VERSION "f33"
NS_ :

BS_:
BU_: RR RL FL FR GEN

CM_ "Dummy messages for use in the C files. These will never be sent over CAN,
    it is only to make the C code more generic";

BO_ 000 ERPM_DUTY_VOLTAGE: 8 GEN
 SG_ ERPM : 7|32@1- (1,0) [-120000|1200000] "" Vector__XXX
 SG_ Duty : 39|16@1- (0.1,0) [-100|100] "%" Vector__XXX
 SG_ InputVoltage : 55|16@1- (1,0) [0|1000] "V" Vector__XXX

BO_ 001 AC_DC_CURRENT: 8 GEN
 SG_ AC_Current : 7|16@0- (0.1,0) [-850|850] "A"  Vector_XXX
 SG_ DC_Current : 23|16@0- (0.1,0) [-850|850] "A"  Vector_XXX

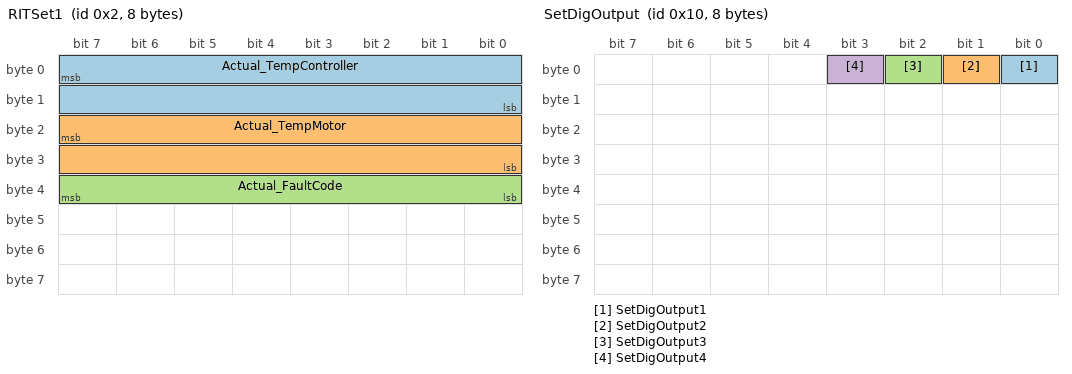
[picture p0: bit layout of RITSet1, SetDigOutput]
BO_ 002 RITSet1: 8 GEN
 SG_ Actual_TempController : 7|16@0- (0.1,0) [-55|200] "C"  Vector__XXX
 SG_ Actual_TempMotor : 23|16@0- (0.1,0) [-55|200] "C"  Vector__XXX
 SG_ Actual_FaultCode : 39|8@0+ (1,0) [0|255] ""  Vector__XXX

BO_ 003 RITSet2: 8 GEN
 SG_ Actual_FOC_id : 7|32@0- (0.01,0) [-850|850] "Apk"  Vector__XXX
 SG_ Actual_FOC_iq : 39|32@0- (0.01,0) [-850|850] "Apk"  Vector__XXX

BO_ 004 RITSet3: 4 GEN
 SG_ Actual_Throttle : 7|8@0- (1,0) [0|100] "%"  Vector__XXX
 SG_ Actual_Brake : 15|8@0- (1,0) [0|100] "%"  Vector__XXX
 SG_ Digital_input_1 : 16|1@0+ (1,0) [0|1] ""  Vector__XXX
 SG_ Digital_input_2 : 17|1@0+ (1,0) [0|1] ""  Vector__XXX
 SG_ Digital_input_3 : 18|1@0+ (1,0) [0|1] ""  Vector__XXX
 SG_ Digital_input_4 : 19|1@0+ (1,0) [0|1] ""  Vector__XXX
 SG_ Drive_enable : 31|8@0+ (1,0) [0|1] ""  Vector__XXX
 SG_ Capacitor_temp_limit : 32|1@0+ (1,0) [0|1] ""  Vector__XXX
 SG_ DC_current_limit : 33|1@0+ (1,0) [0|1] ""  Vector__XXX
 SG_ Drive_enable_limit : 34|1@0+ (1,0) [0|1] ""  Vector__XXX
 SG_ IGBT_accel_limit : 35|1@0+ (1,0) [0|1] ""  Vector__XXX
 SG_ IGBT_temp_limit : 36|1@0+ (1,0) [0|1] ""  Vector__XXX
 SG_ Input_voltage_limit : 37|1@0+ (1,0) [0|1] ""  Vector__XXX
 SG_ Motor_accel_limit : 38|1@0+ (1,0) [0|1] ""  Vector__XXX
 SG_ Motor_temp_limit : 39|1@0+ (1,0) [0|1] ""  Vector__XXX
 SG_ RPM_min_limit : 40|1@0+ (1,0) [0|1] ""  Vector__XXX
 SG_ RPM_max_limit : 41|1@0+ (1,0) [0|1] ""  Vector__XXX
 SG_ Power_limit : 42|1@0+ (1,0) [0|1] ""  Vector__XXX
 SG_ CAN_map_version : 63|8@0+ (0.1,0) [0|255] "Version"  Vector__XXX

BO_ 005 Setpoints: 8 GEN
 SG_ DriveEnable : 7|8@0+ (1,0) [0|1] ""  Vector__XXX

BO_ 006 SetAcCurrent: 8 GEN
 SG_ TargetAcCurrent : 7|16@0- (0.1,0) [-850|850] "A"  Vector__XXX

BO_ 007 SetBrakeCurrent: 8 GEN
 SG_ TargetBrakeCurrent : 7|16@0- (0.1,0) [0|850] "A"  Vector__XXX

BO_ 008 SetERPM: 4 GEN
 SG_ TargetSpeed : 7|32@0- (1,0) [-100000|100000] "ERPM"  Vector__XXX

BO_ 009 SetPosition: 2 GEN
 SG_ TargetPosition : 7|16@0- (0.1,0) [0|359] "degree"  Vector__XXX

BO_ 010 SetRelCurrent: 2 GEN
 SG_ TargetRelativeCurrent : 7|16@0- (0.1,0) [-100|100] "%"  Vector__XXX

BO_ 011 SetRelBrakeCurrent: 2 GEN
 SG_ TargeRelativeBrakeCurrent : 7|16@0- (0.1,0) [0|100] "%"  Vector__XXX

BO_ 012 SetMaxAcCurrent: 2 GEN
 SG_ MaxAcCurrent : 7|16@0- (0.1,0) [0|850] "A"  Vector__XXX

BO_ 013 SetMaxAcBrakeCurrent: 2 GEN
 SG_ MaxAcBrakeCurrent : 7|16@0- (0.1,0) [-850|0] "A"  Vector__XXX

BO_ 014 SetMaxDcCurrent: 2 GEN
 SG_ MaxDcCurrent : 7|16@0- (0.1,0) [0|850] "A"  Vector__XXX

BO_ 015 SetMaxDcBrakeCurrent: 2 GEN
 SG_ MaxDcBrakeCurrent : 7|16@0- (0.1,0) [-850|0] "A"  Vector__XXX

BO_ 016 SetDigOutput: 8 GEN
 SG_ SetDigOutput1 : 0|1@0+ (1,0) [0|1] "#" Vector__XXX
 SG_ SetDigOutput2 : 1|1@0+ (1,0) [0|1] "#" Vector__XXX
 SG_ SetDigOutput3 : 2|1@0+ (1,0) [0|1] "#" Vector__XXX
 SG_ SetDigOutput4 : 3|1@0+ (1,0) [0|1] "#" Vector__XXX

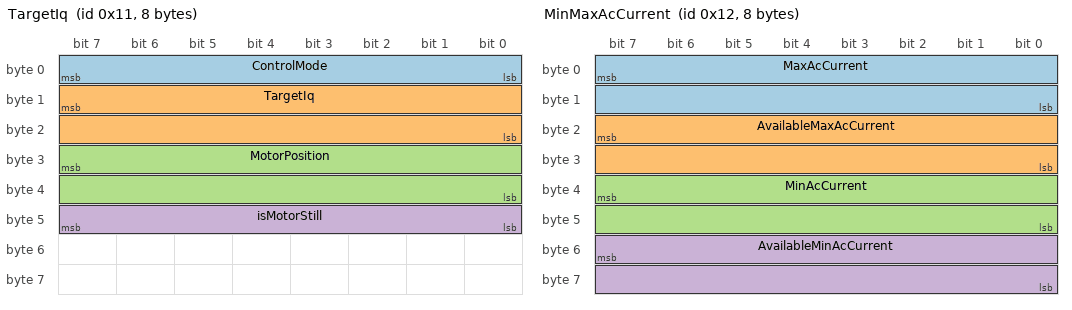
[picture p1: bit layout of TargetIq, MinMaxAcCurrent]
BO_ 017 TargetIq: 8 GEN
 SG_ ControlMode : 7|8@0+ (1,0) [0|7] "#" Vector__XXX
 SG_ TargetIq : 15|16@0- (0.1,0) [-850|850] "Apk" Vector__XXX
 SG_ MotorPosition : 31|16@0+ (0.1,0) [0|359] "degree" Vector__XXX
 SG_ isMotorStill : 47|8@0+ (1,0) [0|1] "#" Vector__XXX

BO_ 018 MinMaxAcCurrent: 8 GEN
 SG_ MaxAcCurrent : 7|16@0- (0.1,0) [0|850] "Apk" Vector__XXX
 SG_ AvailableMaxAcCurrent : 23|16@0- (0.1,0) [0|850] "Apk" Vector__XXX
 SG_ MinAcCurrent : 39|16@0- (0.1,0) [-850|0] "Apk" Vector__XXX
 SG_ AvailableMinAcCurrent : 55|16@0- (0.1,0) [-850|0] "Apk" Vector__XXX

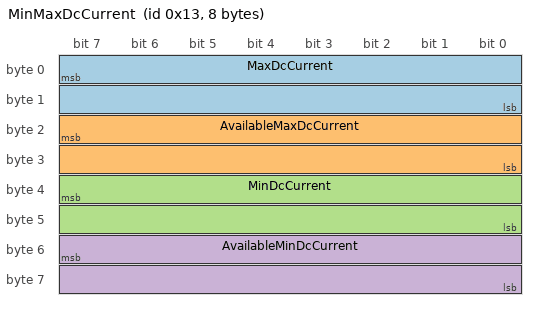
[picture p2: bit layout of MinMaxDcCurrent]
BO_ 019 MinMaxDcCurrent: 8 GEN
 SG_ MaxDcCurrent : 7|16@0- (0.1,0) [0|850] "Adc" Vector__XXX
 SG_ AvailableMaxDcCurrent : 23|16@0- (0.1,0) [0|850] "Adc" Vector__XXX
 SG_ MinDcCurrent : 39|16@0- (0.1,0) [-850|0] "Adc" Vector__XXX
 SG_ AvailableMinDcCurrent : 55|16@0- (0.1,0) [-850|0] "Adc" Vector__XXX
